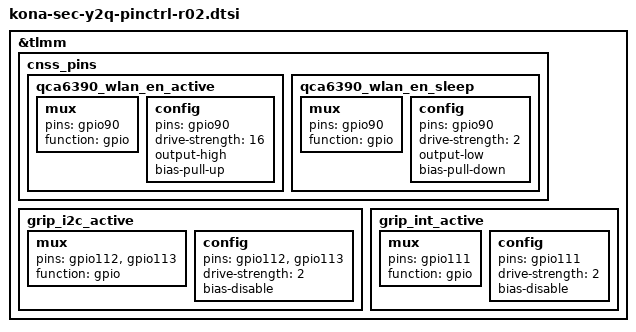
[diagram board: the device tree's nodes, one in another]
/* Copyright (c) 2019, The Linux Foundation. All rights reserved.
 *
 * This program is free software; you can redistribute it and/or modify
 * it under the terms of the GNU General Public License version 2 and
 * only version 2 as published by the Free Software Foundation.
 *
 * This program is distributed in the hope that it will be useful,
 * but WITHOUT ANY WARRANTY; without even the implied warranty of
 * MERCHANTABILITY or FITNESS FOR A PARTICULAR PURPOSE.  See the
 * GNU General Public License for more details.
 */

/*
 * CAUTION:
 * Do NOT inherit from previous revision of dtsi files
 * since it was only for used for bring-up
 */
#include "../drivers/audio_qca_picasso_pinctrl_common.dtsi"
#include "../drivers/kona-sec-picasso-display-pinctrl.dtsi"
#include "../drivers/kona-sec-picasso-mfc-pinctrl.dtsi"
#include "../drivers/kona-sec-hubble-tsp-pinctrl.dtsi"
#include "../drivers/bluetooth_picasso_pinctrl_common.dtsi"
#include "../drivers/kona-sec-y2q-camera-sensor-pinctrl-r02.dtsi"

&tlmm {
	cnss_pins {
        	qca6390_wlan_en_active: qca6390_wlan_en_active {
                	mux {
                        	pins = "gpio90";
                                function = "gpio";
                        };

                        config {
                        	pins = "gpio90";
                                drive-strength = <16>;
                                output-high;
                                bias-pull-up;
                        };
                };

                qca6390_wlan_en_sleep: qca6390_wlan_en_sleep {
                	mux {
                        	pins = "gpio90";
                                function = "gpio";
                        };

                        config {
                        	pins = "gpio90";
                                drive-strength = <2>;
                                output-low;
                                bias-pull-down;
                        };
                };
        };

	grip_i2c_active: grip_i2c_active {
		mux {
			pins = "gpio112", "gpio113";
			function = "gpio";
		};
		config {
			pins = "gpio112", "gpio113";
			drive-strength = <2>;
			bias-disable;
		};
	};

	grip_int_active: grip_int_active {
		mux {
			pins = "gpio111";
			function = "gpio";
		};
		config {
			pins = "gpio111";
			drive-strength = <2>;
			bias-disable;
		};
	};
};
